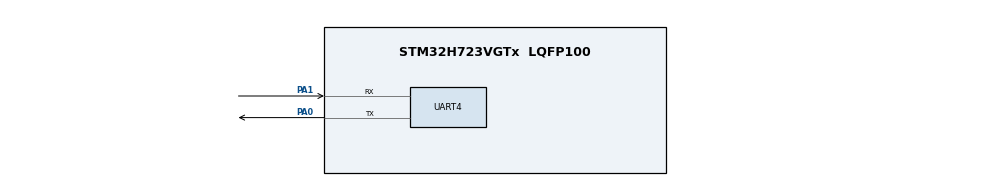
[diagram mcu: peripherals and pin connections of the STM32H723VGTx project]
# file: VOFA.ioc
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CORTEX_M7.default_mode_Activation=1
Dma.Request0=UART4_TX
Dma.UART4_TX.0.Direction=DMA_MEMORY_TO_PERIPH
Dma.UART4_TX.0.EventEnable=DISABLE
Dma.UART4_TX.0.FIFOMode=DMA_FIFOMODE_DISABLE
Dma.UART4_TX.0.Instance=DMA1_Stream0
Dma.UART4_TX.0.MemDataAlignment=DMA_MDATAALIGN_BYTE
Dma.UART4_TX.0.MemInc=DMA_MINC_ENABLE
Dma.UART4_TX.0.Mode=DMA_NORMAL
Dma.UART4_TX.0.PeriphDataAlignment=DMA_PDATAALIGN_BYTE
Dma.UART4_TX.0.PeriphInc=DMA_PINC_DISABLE
Dma.UART4_TX.0.Polarity=HAL_DMAMUX_REQ_GEN_RISING
Dma.UART4_TX.0.Priority=DMA_PRIORITY_LOW
Dma.UART4_TX.0.RequestNumber=1
Dma.UART4_TX.0.SignalID=NONE
Dma.UART4_TX.0.SyncEnable=DISABLE
Dma.UART4_TX.0.SyncPolarity=HAL_DMAMUX_SYNC_NO_EVENT
Dma.UART4_TX.0.SyncRequestNumber=1
Dma.UART4_TX.0.SyncSignalID=NONE
Mcu.Family=STM32H7
Mcu.Name=STM32H723VGTx
Mcu.Package=LQFP100
NVIC.DMA1_Stream0_IRQn=true\:0\:0\:false\:false\:true\:false\:true\:true
NVIC.PriorityGroup=NVIC_PRIORITYGROUP_4
NVIC.UART4_IRQn=true\:0\:0\:false\:false\:true\:true\:true\:true
PA0.Mode=Asynchronous
PA0.Signal=UART4_TX
PA1.Mode=Asynchronous
PA1.Signal=UART4_RX
PA13(JTMS/SWDIO).Mode=Serial_Wire
PA13(JTMS/SWDIO).Signal=DEBUG_JTMS-SWDIO
PA14(JTCK/SWCLK).Mode=Serial_Wire
PA14(JTCK/SWCLK).Signal=DEBUG_JTCK-SWCLK
PH0-OSC_IN.Mode=HSE-External-Clock-Source
PH0-OSC_IN.Signal=RCC_OSC_IN
ProjectManager.HeapSize=0x200
ProjectManager.StackSize=0x400
ProjectManager.TargetToolchain=MDK-ARM V5.32
RCC.ADCFreq_Value=129000000
RCC.APB1Freq_Value=137500000
RCC.APB2Freq_Value=137500000
RCC.APB3Freq_Value=137500000
RCC.APB4Freq_Value=137500000
RCC.CortexFreq_Value=550000000
RCC.D1PPRE=RCC_APB3_DIV2
RCC.D2PPRE1=RCC_APB1_DIV2
RCC.D2PPRE2=RCC_APB2_DIV2
RCC.D3PPRE=RCC_APB4_DIV2
RCC.DIVM1=4
RCC.DIVN1=34
RCC.DIVP1=1
RCC.HCLKFreq_Value=275000000
RCC.HPRE=RCC_HCLK_DIV2
RCC.PLL2FRACN=0
RCC.PLL3FRACN=0
RCC.PLLFRACN=3072
RCC.SYSCLKFreq_VALUE=550000000
RCC.SYSCLKSource=RCC_SYSCLKSOURCE_PLLCLK
RCC.USBFreq_Value=275000000
VP_MEMORYMAP_VS_MEMORYMAP.Mode=CurAppReg
board=custom

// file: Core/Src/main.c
/* USER CODE BEGIN Header */
/**
  ******************************************************************************
  * @file           : main.c
  * @brief          : Main program body
  ******************************************************************************
  * @attention
  *
  * Copyright (c) 2026 STMicroelectronics.
  * All rights reserved.
  *
  * This software is licensed under terms that can be found in the LICENSE file
  * in the root directory of this software component.
  * If no LICENSE file comes with this software, it is provided AS-IS.
  *
  ******************************************************************************
  */
/* USER CODE END Header */
#include "main.h"

UART_HandleTypeDef huart4;
DMA_HandleTypeDef hdma_uart4_tx;

void SystemClock_Config(void);
static void MPU_Config(void);
static void MX_GPIO_Init(void);
static void MX_DMA_Init(void);
static void MX_UART4_Init(void);
/* USER CODE BEGIN PFP */
void _loop(void);

/* USER CODE END PFP */

int main(void)
{

  /* MPU Configuration--------------------------------------------------------*/
  MPU_Config();

  /* MCU Configuration--------------------------------------------------------*/

  /* Reset of all peripherals, Initializes the Flash interface and the Systick. */
  HAL_Init();

  /* Configure the system clock */
  SystemClock_Config();

  /* Initialize all configured peripherals */
  MX_GPIO_Init();
  MX_DMA_Init();
  MX_UART4_Init();

  /* Infinite loop */
  while (1)
  {

    /* USER CODE BEGIN 3 */
    _loop();
  }
  /* USER CODE END 3 */
}

void SystemClock_Config(void)
{
  RCC_OscInitTypeDef RCC_OscInitStruct = {0};
  RCC_ClkInitTypeDef RCC_ClkInitStruct = {0};

  /** Supply configuration update enable
  */
  HAL_PWREx_ConfigSupply(PWR_LDO_SUPPLY);

  /** Configure the main internal regulator output voltage
  */
  __HAL_PWR_VOLTAGESCALING_CONFIG(PWR_REGULATOR_VOLTAGE_SCALE0);

  while(!__HAL_PWR_GET_FLAG(PWR_FLAG_VOSRDY)) {}

  /** Initializes the RCC Oscillators according to the specified parameters
  * in the RCC_OscInitTypeDef structure.
  */
  RCC_OscInitStruct.OscillatorType = RCC_OSCILLATORTYPE_HSI;
  RCC_OscInitStruct.HSIState = RCC_HSI_DIV1;
  RCC_OscInitStruct.HSICalibrationValue = 64;
  RCC_OscInitStruct.PLL.PLLState = RCC_PLL_ON;
  RCC_OscInitStruct.PLL.PLLSource = RCC_PLLSOURCE_HSI;
  RCC_OscInitStruct.PLL.PLLM = 4;
  RCC_OscInitStruct.PLL.PLLN = 34;
  RCC_OscInitStruct.PLL.PLLP = 1;
  RCC_OscInitStruct.PLL.PLLQ = 2;
  RCC_OscInitStruct.PLL.PLLR = 2;
  RCC_OscInitStruct.PLL.PLLRGE = RCC_PLL1VCIRANGE_3;
  RCC_OscInitStruct.PLL.PLLVCOSEL = RCC_PLL1VCOWIDE;
  RCC_OscInitStruct.PLL.PLLFRACN = 3072;
  if (HAL_RCC_OscConfig(&RCC_OscInitStruct) != HAL_OK)
  {
    Error_Handler();
  }

  /** Initializes the CPU, AHB and APB buses clocks
  */
  RCC_ClkInitStruct.ClockType = RCC_CLOCKTYPE_HCLK|RCC_CLOCKTYPE_SYSCLK
                              |RCC_CLOCKTYPE_PCLK1|RCC_CLOCKTYPE_PCLK2
                              |RCC_CLOCKTYPE_D3PCLK1|RCC_CLOCKTYPE_D1PCLK1;
  RCC_ClkInitStruct.SYSCLKSource = RCC_SYSCLKSOURCE_PLLCLK;
  RCC_ClkInitStruct.SYSCLKDivider = RCC_SYSCLK_DIV1;
  RCC_ClkInitStruct.AHBCLKDivider = RCC_HCLK_DIV2;
  RCC_ClkInitStruct.APB3CLKDivider = RCC_APB3_DIV2;
  RCC_ClkInitStruct.APB1CLKDivider = RCC_APB1_DIV2;
  RCC_ClkInitStruct.APB2CLKDivider = RCC_APB2_DIV2;
  RCC_ClkInitStruct.APB4CLKDivider = RCC_APB4_DIV2;

  if (HAL_RCC_ClockConfig(&RCC_ClkInitStruct, FLASH_LATENCY_3) != HAL_OK)
  {
    Error_Handler();
  }
}

static void MX_UART4_Init(void)
{

  huart4.Instance = UART4;
  huart4.Init.BaudRate = 115200;
  huart4.Init.WordLength = UART_WORDLENGTH_8B;
  huart4.Init.StopBits = UART_STOPBITS_1;
  huart4.Init.Parity = UART_PARITY_NONE;
  huart4.Init.Mode = UART_MODE_TX_RX;
  huart4.Init.HwFlowCtl = UART_HWCONTROL_NONE;
  huart4.Init.OverSampling = UART_OVERSAMPLING_16;
  huart4.Init.OneBitSampling = UART_ONE_BIT_SAMPLE_DISABLE;
  huart4.Init.ClockPrescaler = UART_PRESCALER_DIV1;
  huart4.AdvancedInit.AdvFeatureInit = UART_ADVFEATURE_NO_INIT;
  if (HAL_UART_Init(&huart4) != HAL_OK)
  {
    Error_Handler();
  }
  if (HAL_UARTEx_SetTxFifoThreshold(&huart4, UART_TXFIFO_THRESHOLD_1_8) != HAL_OK)
  {
    Error_Handler();
  }
  if (HAL_UARTEx_SetRxFifoThreshold(&huart4, UART_RXFIFO_THRESHOLD_1_8) != HAL_OK)
  {
    Error_Handler();
  }
  if (HAL_UARTEx_DisableFifoMode(&huart4) != HAL_OK)
  {
    Error_Handler();
  }

}

static void MX_DMA_Init(void)
{

  /* DMA controller clock enable */
  __HAL_RCC_DMA1_CLK_ENABLE();

  /* DMA interrupt init */
  /* DMA1_Stream0_IRQn interrupt configuration */
  HAL_NVIC_SetPriority(DMA1_Stream0_IRQn, 0, 0);
  HAL_NVIC_EnableIRQ(DMA1_Stream0_IRQn);

}

static void MX_GPIO_Init(void)
{

  /* GPIO Ports Clock Enable */
  __HAL_RCC_GPIOH_CLK_ENABLE();
  __HAL_RCC_GPIOA_CLK_ENABLE();

}

 /* MPU Configuration */

void MPU_Config(void)
{
  MPU_Region_InitTypeDef MPU_InitStruct = {0};

  /* Disables the MPU */
  HAL_MPU_Disable();

  /** Initializes and configures the Region and the memory to be protected
  */
  MPU_InitStruct.Enable = MPU_REGION_ENABLE;
  MPU_InitStruct.Number = MPU_REGION_NUMBER0;
  MPU_InitStruct.BaseAddress = 0x0;
  MPU_InitStruct.Size = MPU_REGION_SIZE_4GB;
  MPU_InitStruct.SubRegionDisable = 0x87;
  MPU_InitStruct.TypeExtField = MPU_TEX_LEVEL0;
  MPU_InitStruct.AccessPermission = MPU_REGION_NO_ACCESS;
  MPU_InitStruct.DisableExec = MPU_INSTRUCTION_ACCESS_DISABLE;
  MPU_InitStruct.IsShareable = MPU_ACCESS_SHAREABLE;
  MPU_InitStruct.IsCacheable = MPU_ACCESS_NOT_CACHEABLE;
  MPU_InitStruct.IsBufferable = MPU_ACCESS_NOT_BUFFERABLE;

  HAL_MPU_ConfigRegion(&MPU_InitStruct);
  /* Enables the MPU */
  HAL_MPU_Enable(MPU_PRIVILEGED_DEFAULT);

}

void Error_Handler(void)
{
  __disable_irq();
  while (1)
  {
  }
}
